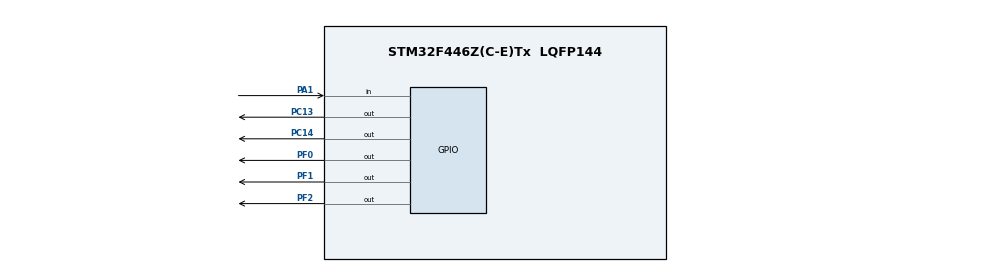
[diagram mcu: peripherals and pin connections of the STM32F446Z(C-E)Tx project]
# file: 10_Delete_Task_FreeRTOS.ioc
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FREERTOS.Tasks01=Task1,27,128,Task1_Handler,Default,NULL,Dynamic,NULL,NULL;Task2,29,128,Task2_Handler,Default,NULL,Dynamic,NULL,NULL
Mcu.Family=STM32F4
Mcu.Name=STM32F446Z(C-E)Tx
Mcu.Package=LQFP144
NVIC.PriorityGroup=NVIC_PRIORITYGROUP_4
NVIC.TIM1_UP_TIM10_IRQn=true\:15\:0\:false\:false\:true\:false\:false\:true\:true
NVIC.TimeBase=TIM1_UP_TIM10_IRQn
NVIC.TimeBaseIP=TIM1
PA1.Signal=GPIO_Input
PA13.Mode=Serial_Wire
PA13.Signal=SYS_JTMS-SWDIO
PA14.Mode=Serial_Wire
PA14.Signal=SYS_JTCK-SWCLK
PC13.Signal=GPIO_Output
PC14-OSC32_IN.Signal=GPIO_Output
PF0.Signal=GPIO_Output
PF1.Signal=GPIO_Output
PF2.Signal=GPIO_Output
ProjectManager.HeapSize=0x200
ProjectManager.StackSize=0x400
ProjectManager.TargetToolchain=STM32CubeIDE
RCC.CortexFreq_Value=16000000
RCC.USBFreq_Value=96000000
RCC.VCOOutputFreq_Value=192000000
VP_FREERTOS_VS_CMSIS_V2.Mode=CMSIS_V2
VP_SYS_VS_tim1.Mode=TIM1
board=custom

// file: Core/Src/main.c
/* USER CODE BEGIN Header */
/**
  ******************************************************************************
  * @file           : main.c
  * @brief          : Main program body
  ******************************************************************************
  * @attention
  *
  * Copyright (c) 2024 STMicroelectronics.
  * All rights reserved.
  *
  * This software is licensed under terms that can be found in the LICENSE file
  * in the root directory of this software component.
  * If no LICENSE file comes with this software, it is provided AS-IS.
  *
  ******************************************************************************
  */
/* USER CODE END Header */
#include "main.h"
#include "cmsis_os.h"

/* Definitions for Task1 */
osThreadId_t Task1Handle;
const osThreadAttr_t Task1_attributes = {
  .name = "Task1",
  .stack_size = 128 * 4,
  .priority = (osPriority_t) osPriorityNormal3,
};
/* Definitions for Task2 */
osThreadId_t Task2Handle;
const osThreadAttr_t Task2_attributes = {
  .name = "Task2",
  .stack_size = 128 * 4,
  .priority = (osPriority_t) osPriorityNormal5,
};

void SystemClock_Config(void);
static void MX_GPIO_Init(void);
void Task1_Handler(void *argument);
void Task2_Handler(void *argument);

int main(void)
{

  /* MCU Configuration--------------------------------------------------------*/

  /* Reset of all peripherals, Initializes the Flash interface and the Systick. */
  HAL_Init();

  /* Configure the system clock */
  SystemClock_Config();

  /* Initialize all configured peripherals */
  MX_GPIO_Init();

  /* Init scheduler */
  osKernelInitialize();

  /* Create the thread(s) */
  /* creation of Task1 */
  Task1Handle = osThreadNew(Task1_Handler, NULL, &Task1_attributes);

  /* creation of Task2 */
  Task2Handle = osThreadNew(Task2_Handler, NULL, &Task2_attributes);

  /* Start scheduler */
  osKernelStart();

  /* We should never get here as control is now taken by the scheduler */
  /* Infinite loop */
  while (1)
  {

  }
}

void SystemClock_Config(void)
{
  RCC_OscInitTypeDef RCC_OscInitStruct = {0};
  RCC_ClkInitTypeDef RCC_ClkInitStruct = {0};

  /** Configure the main internal regulator output voltage
  */
  __HAL_RCC_PWR_CLK_ENABLE();
  __HAL_PWR_VOLTAGESCALING_CONFIG(PWR_REGULATOR_VOLTAGE_SCALE3);

  /** Initializes the RCC Oscillators according to the specified parameters
  * in the RCC_OscInitTypeDef structure.
  */
  RCC_OscInitStruct.OscillatorType = RCC_OSCILLATORTYPE_HSI;
  RCC_OscInitStruct.HSIState = RCC_HSI_ON;
  RCC_OscInitStruct.HSICalibrationValue = RCC_HSICALIBRATION_DEFAULT;
  RCC_OscInitStruct.PLL.PLLState = RCC_PLL_NONE;
  if (HAL_RCC_OscConfig(&RCC_OscInitStruct) != HAL_OK)
  {
    Error_Handler();
  }

  /** Initializes the CPU, AHB and APB buses clocks
  */
  RCC_ClkInitStruct.ClockType = RCC_CLOCKTYPE_HCLK|RCC_CLOCKTYPE_SYSCLK
                              |RCC_CLOCKTYPE_PCLK1|RCC_CLOCKTYPE_PCLK2;
  RCC_ClkInitStruct.SYSCLKSource = RCC_SYSCLKSOURCE_HSI;
  RCC_ClkInitStruct.AHBCLKDivider = RCC_SYSCLK_DIV1;
  RCC_ClkInitStruct.APB1CLKDivider = RCC_HCLK_DIV1;
  RCC_ClkInitStruct.APB2CLKDivider = RCC_HCLK_DIV1;

  if (HAL_RCC_ClockConfig(&RCC_ClkInitStruct, FLASH_LATENCY_0) != HAL_OK)
  {
    Error_Handler();
  }
}

static void MX_GPIO_Init(void)
{
  GPIO_InitTypeDef GPIO_InitStruct = {0};

  /* GPIO Ports Clock Enable */
  __HAL_RCC_GPIOC_CLK_ENABLE();
  __HAL_RCC_GPIOF_CLK_ENABLE();
  __HAL_RCC_GPIOA_CLK_ENABLE();

  /*Configure GPIO pin Output Level */
  HAL_GPIO_WritePin(GPIOC, GPIO_PIN_13|GPIO_PIN_14, GPIO_PIN_RESET);

  /*Configure GPIO pin Output Level */
  HAL_GPIO_WritePin(GPIOF, GPIO_PIN_0|GPIO_PIN_1|GPIO_PIN_2, GPIO_PIN_RESET);

  /*Configure GPIO pins : PC13 PC14 */
  GPIO_InitStruct.Pin = GPIO_PIN_13|GPIO_PIN_14;
  GPIO_InitStruct.Mode = GPIO_MODE_OUTPUT_PP;
  GPIO_InitStruct.Pull = GPIO_NOPULL;
  GPIO_InitStruct.Speed = GPIO_SPEED_FREQ_LOW;
  HAL_GPIO_Init(GPIOC, &GPIO_InitStruct);

  /*Configure GPIO pins : PF0 PF1 PF2 */
  GPIO_InitStruct.Pin = GPIO_PIN_0|GPIO_PIN_1|GPIO_PIN_2;
  GPIO_InitStruct.Mode = GPIO_MODE_OUTPUT_PP;
  GPIO_InitStruct.Pull = GPIO_NOPULL;
  GPIO_InitStruct.Speed = GPIO_SPEED_FREQ_LOW;
  HAL_GPIO_Init(GPIOF, &GPIO_InitStruct);

  /*Configure GPIO pin : PA1 */
  GPIO_InitStruct.Pin = GPIO_PIN_1;
  GPIO_InitStruct.Mode = GPIO_MODE_INPUT;
  GPIO_InitStruct.Pull = GPIO_NOPULL;
  HAL_GPIO_Init(GPIOA, &GPIO_InitStruct);

}

/* USER CODE BEGIN 4 */
void freeRTOS_Delay(uint32_t delayMS)
{
	uint32_t currentTick = xTaskGetTickCount();
	uint32_t delayTick = pdMS_TO_TICKS(delayMS);
	while(xTaskGetTickCount() < (currentTick + delayTick));
}
/* USER CODE END 4 */

void Task1_Handler(void *argument)
{
  /* USER CODE BEGIN 5 */
  /* Infinite loop */
  for(;;)
  {
	  HAL_GPIO_TogglePin(GPIOF, GPIO_PIN_0 | GPIO_PIN_1 | GPIO_PIN_2);

    //osDelay(200); osDelay beklerken görev önceliği düşük task çalışıyor bunu önlemek için kendi delay fonk yazdık hal_delay da kullansak olurdu ama biz hazır fonk yazdık
	  freeRTOS_Delay(200);

  }
  /* USER CODE END 5 */
}

void Task2_Handler(void *argument)
{
  /* USER CODE BEGIN Task2_Handler */
  /* Infinite loop */
  for(;;)
  {
	  HAL_GPIO_TogglePin(GPIOC, GPIO_PIN_13 | GPIO_PIN_14);
      HAL_Delay(100);

      if(HAL_GPIO_ReadPin(GPIOA, GPIO_PIN_1) == GPIO_PIN_SET)
      {
    	  osThreadSuspend(Task2Handle);

      }
  }
  /* USER CODE END Task2_Handler */
}

void HAL_TIM_PeriodElapsedCallback(TIM_HandleTypeDef *htim)
{
  if (htim->Instance == TIM1) {
    HAL_IncTick();
  }
}

void Error_Handler(void)
{
  __disable_irq();
  while (1)
  {
  }
}
